AUTOSAR XML (schema 4-3-0)
# \copyright BMW AG 2015 - 2017
package /BMW/Platform/StdDiag/SwcImplementations
  swc implementation Impl_StdDiag: programming-language=C, sw-version=5.4.0, swc-bsw-mapping=StdDiagSwcBswMapping, vendor-id=5, behavior=IntBhv_StdDiag
    code-descriptors:
      code Code1: artifact-descriptors=autosar-engineering-object={short-label=-, category=-}
    resource consumption ResConsumption1
package /BMW/Platform/StdDiag/SwComponentTypes
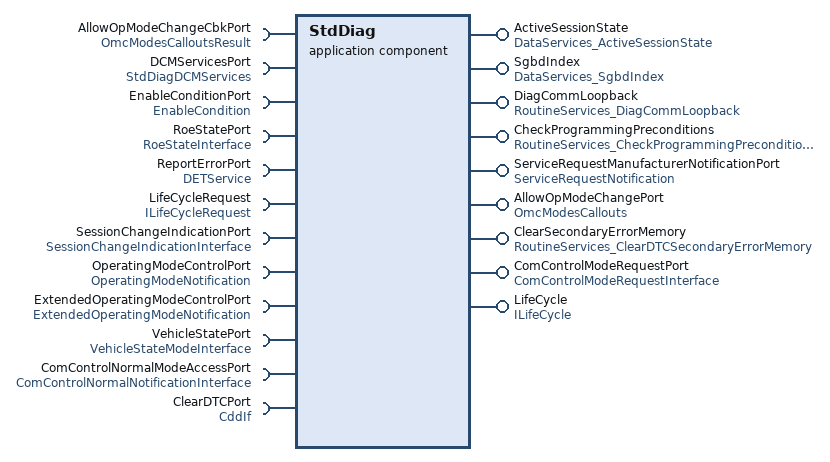
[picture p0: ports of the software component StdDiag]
  application sw component type StdDiag
    6 x provide port:
      ActiveSessionState: provided-interface=DataServices_ActiveSessionState
      SgbdIndex: provided-interface=DataServices_SgbdIndex
      DiagCommLoopback: provided-interface=RoutineServices_DiagCommLoopback
      CheckProgrammingPreconditions: provided-interface=RoutineServices_CheckProgrammingPreconditions
      ServiceRequestManufacturerNotificationPort: provided-interface=ServiceRequestNotification
      AllowOpModeChangePort: provided-interface=OmcModesCallouts
    require port AllowOpModeChangeCbkPort: required-interface=OmcModesCalloutsResult
    provide port ClearSecondaryErrorMemory: provided-interface=RoutineServices_ClearDTCSecondaryErrorMemory
    provide port ComControlModeRequestPort: provided-interface=ComControlModeRequestInterface
    provide port LifeCycle: mode-switch-sender-com-spec{enhanced-mode-api=true, mode-group=Mode, queue-length=2}, provided-interface=ILifeCycle
    11 x require port:
      DCMServicesPort: required-interface=StdDiagDCMServices
      EnableConditionPort: required-interface=EnableCondition
      RoeStatePort: required-interface=RoeStateInterface
      ReportErrorPort: required-interface=DETService
      LifeCycleRequest: nonqueued-receiver-com-spec{data-element=requestMode, init-value=2}, required-interface=ILifeCycleRequest
      SessionChangeIndicationPort: required-interface=SessionChangeIndicationInterface
      OperatingModeControlPort: required-interface=OperatingModeNotification
      ExtendedOperatingModeControlPort: required-interface=ExtendedOperatingModeNotification
      VehicleStatePort: required-interface=VehicleStateModeInterface
      ComControlNormalModeAccessPort: required-interface=ComControlNormalNotificationInterface
      ClearDTCPort: required-interface=CddIf
    behavior IntBhv_StdDiag: data-type-mapping=[StdDiag_DataTypeMappingSet, Omc_DataTypeMappingSets, Stm_VehicleStatModeRequestTypeMap], handle-termination-and-restart=NO-SUPPORT
      swc mode switch event Event_SessionChange_DefaultSession: start-on-event=SessionChange_DefaultSession, activation=ON-ENTRY, mode=SessionChangeIndicationPort.SessionModeDeclarationGroup.STDDIAG_DEFAULT_SESSION
      swc mode switch event Event_SessionChange_OtherSession: start-on-event=SessionChange_OtherSession, activation=ON-ENTRY, mode=SessionChangeIndicationPort.SessionModeDeclarationGroup.STDDIAG_OTHER_SESSION
      data received event LifeCycleRequest: start-on-event=LifeCycleHandler, data=LifeCycleRequest.requestMode
      10 x operation invoked event:
        Event_ManufacturerIndication: start-on-event=ManufacturerIndication, operation=ServiceRequestManufacturerNotificationPort.Indication
        Event_ManufacturerConfirmation: start-on-event=ManufacturerConfirmation, operation=ServiceRequestManufacturerNotificationPort.Confirmation
        Event_AllowOpModeChange: start-on-event=AllowOpModeChange, operation=AllowOpModeChangePort.AllowOpModeSwitch
        Event_OpModeChangeCancelled: start-on-event=OpModeChangeCancelled, operation=AllowOpModeChangePort.OpModeSwitchCancelled
        Event_ConditionCheckActiveSessionState: start-on-event=ConditionCheckActiveSessionState, operation=ActiveSessionState.ConditionCheckRead
        Event_ReadDataActiveSessionState: start-on-event=ReadDataActiveSessionState, operation=ActiveSessionState.ReadData
        Event_ReadDataSgbdIndex: start-on-event=ReadDataSgbdIndex, operation=SgbdIndex.ReadData
        Event_RoutineControlStartDiagCommLoopback: start-on-event=RoutineControlStartDiagCommLoopback, operation=DiagCommLoopback.Start
        Event_RoutineControlStartCheckProgrammingPreconditions: start-on-event=RoutineControlStartCheckProgrammingPreconditions, operation=CheckProgrammingPreconditions.Start
        Event_RoutineControlStartClearDTCSecondaryErrorMemory: start-on-event=RoutineControlStartClearDTCSecondaryErrorMemory, operation=ClearSecondaryErrorMemory.Start
      13 x runnable:
        LifeCycleHandler: symbol=StdDiag_LifeCycleHandler
          data-read-access:
            access requestedMode: accessed-variable=LifeCycleRequest.requestMode
          data-send-points:
            access VariableAccess_requestComMode: accessed-variable=ComControlModeRequestPort.requestedMode
          mode-access-points:
            LifeCycle.Mode
            OperatingModeControlPort.currentOperatingMode
            ExtendedOperatingModeControlPort.currentExtendedOperatingMode
          mode switch point LifeCycle: mode-group=LifeCycle.Mode
          4 x sync call, all with timeout=0.0:
            sscp_EnableCondition: operation=EnableConditionPort.SetEnableCondition
            sscp_SetRoeSuspended: operation=RoeStatePort.GetRoeState
            sscp_DetError: operation=ReportErrorPort.ReportError
            sscp_DcmGetSesCtrlType: operation=DCMServicesPort.GetSesCtrlType
        ManufacturerIndication: can-be-invoked-concurrently=true, mode-access-point=OperatingModeControlPort.currentOperatingMode, symbol=StdDiag_ManufacturerIndication
          sync call sscp_DetError: operation=ReportErrorPort.ReportError, timeout=0.0
        ManufacturerConfirmation: can-be-invoked-concurrently=true, symbol=StdDiag_ManufacturerConfirmation
          data-send-points:
            access VariableAccess_requestComMode: accessed-variable=ComControlModeRequestPort.requestedMode
          mode-access-points:
            OperatingModeControlPort.currentOperatingMode
            ExtendedOperatingModeControlPort.currentExtendedOperatingMode
            ComControlNormalModeAccessPort.CommunicationModeDeclarationGroup
          sync call sscp_DetError: operation=ReportErrorPort.ReportError, timeout=0.0
          sync call sscp_EnableCondition: operation=EnableConditionPort.SetEnableCondition, timeout=0.0
          sync call sscp_SetRoeSuspended: operation=RoeStatePort.GetRoeState, timeout=0.0
        AllowOpModeChange: can-be-invoked-concurrently=true, mode-access-point=VehicleStatePort.currentVehicleStateMode, symbol=StdDiag_AllowOpModeChange
        OpModeChangeCancelled: can-be-invoked-concurrently=true, symbol=StdDiag_OpModeChangeCancelled
        ReadDataSgbdIndex: can-be-invoked-concurrently=true, symbol=StdDiag_ReadSgbdIndex
        ReadDataActiveSessionState: can-be-invoked-concurrently=true, symbol=StdDiag_ReadActiveSessionState
        ConditionCheckActiveSessionState: can-be-invoked-concurrently=true, symbol=StdDiag_ConditionCheckActiveSessionState
          sync call sscp_DcmGetSesCtrlType: operation=DCMServicesPort.GetSesCtrlType, timeout=0.0
          sync call sscp_DetError: operation=ReportErrorPort.ReportError, timeout=0.0
        RoutineControlStartDiagCommLoopback: can-be-invoked-concurrently=true, symbol=StdDiag_RoutineControlStartDiagCommLoopback
        RoutineControlStartCheckProgrammingPreconditions: can-be-invoked-concurrently=true, symbol=StdDiag_RoutineControlStartCheckProgrammingPreconditions
        SessionChange_DefaultSession: symbol=StdDiag_SesChgIndication_DefaultSession
          data-send-points:
            access VariableAccess_requestComMode: accessed-variable=ComControlModeRequestPort.requestedMode
          mode-access-points:
            OperatingModeControlPort.currentOperatingMode
            ExtendedOperatingModeControlPort.currentExtendedOperatingMode
            ComControlNormalModeAccessPort.CommunicationModeDeclarationGroup
          sync call sscp_DetError: operation=ReportErrorPort.ReportError, timeout=0.0
          sync call sscp_EnableCondition: operation=EnableConditionPort.SetEnableCondition, timeout=0.0
          sync call sscp_SetRoeSuspended: operation=RoeStatePort.GetRoeState, timeout=0.0
        SessionChange_OtherSession: symbol=StdDiag_SesChgIndication_OtherSession
        RoutineControlStartClearDTCSecondaryErrorMemory: can-be-invoked-concurrently=true, symbol=StdDiag_RoutineControlStartClearDTCSecondaryErrorMemory
          sync call sscp_ClearDTC: operation=ClearDTCPort.ClearDTC, timeout=0.0
      7 x swc service dependency:
        StdDiag_DiagnosticValueServiceNeeds_ActiveSessionState: assigned-ports=role-based-port-assignment={port-prototype=ActiveSessionState, role=DataServices}
          service-needs:
            diagnostic value needs sn_StdDiag_DiagnosticValueServiceNeeds_ActiveSessionState: data-length=1, diagnostic-value-access=READ-ONLY, did-number=61696
        StdDiag_DiagnosticCommunicationManagerServiceNeeds_ServiceRequestNotification: assigned-ports=role-based-port-assignment={port-prototype=ServiceRequestManufacturerNotificationPort, role=ServiceRequestNotification}
          service-needs:
            diagnostic communication manager needs sn_StdDiag_DiagnosticCommunicationManagerServiceNeeds
        StdDiag_DiagnosticRoutineServiceNeeds_CheckProgrammingPreconditions: assigned-ports=role-based-port-assignment={port-prototype=CheckProgrammingPreconditions, role=RoutineServices}
          service-needs:
            diagnostic routine needs sn_StdDiag_DiagnosticRoutingServiceNeeds_CheckProgrammingPreconditions: diag-routine-type=SYNCHRONOUS, rid-number=515
        StdDiag_DiagnosticRoutineServiceNeeds_DiagCommLoopBack: assigned-ports=role-based-port-assignment={port-prototype=DiagCommLoopback, role=RoutineServices}
          service-needs:
            diagnostic routine needs sn_StdDiag_DiagnosticRoutingServiceNeeds_DiagCommLoopBack: diag-routine-type=SYNCHRONOUS, rid-number=771
        StdDiag_DiagnosticRoutineServiceNeeds_ClearDTCSecondaryErrorMemory: assigned-ports=role-based-port-assignment={port-prototype=ClearSecondaryErrorMemory, role=RoutineServices}
          service-needs:
            diagnostic routine needs sn_StdDiag_DiagnosticRoutineServiceNeeds_ClearDTCSecondaryErrorMemory: diag-routine-type=ASYNCHRONOUS, rid-number=3846
        StdDiag_DiagnosticCommunicationManagerServiceNeeds_DCMServices: assigned-ports=role-based-port-assignment={port-prototype=DCMServicesPort, role=DCMServices}
          service-needs:
            diagnostic communication manager needs sn_StdDiag_DiagnosticCommunicationManagerServiceNeeds_DCMServices
        StdDiag_DiagnosticEventManagerServiceNeeds_EnableCondition: assigned-ports=role-based-port-assignment={port-prototype=EnableConditionPort, role=EnableCondition}
          service-needs:
            diagnostic event manager needs sn_StdDiag_DiagnosticEventManagerServiceNeeds_EnableCondition
